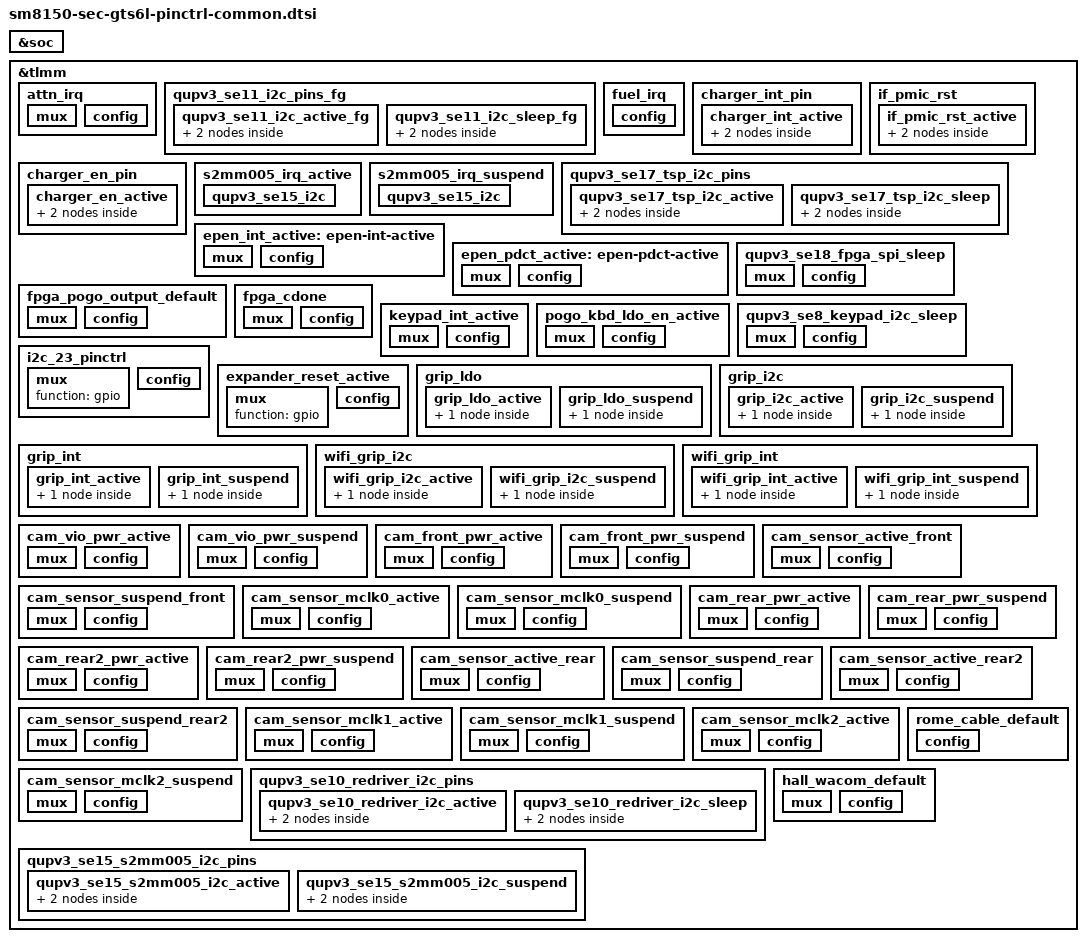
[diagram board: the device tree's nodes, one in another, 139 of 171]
/* Copyright (c) 2016-2018, The Linux Foundation. All rights reserved.
 *
 * This program is free software; you can redistribute it and/or modify
 * it under the terms of the GNU General Public License version 2 and
 * only version 2 as published by the Free Software Foundation.
 *
 * This program is distributed in the hope that it will be useful,
 * but WITHOUT ANY WARRANTY; without even the implied warranty of
 * MERCHANTABILITY or FITNESS FOR A PARTICULAR PURPOSE.  See the
 * GNU General Public License for more details.
 */

#include "sm8150-sec-gts6l-audio-pinctrl.dtsi"

&soc {
};

&tlmm {
	attn_irq: attn_irq {
		mux {
			pins = "gpio87";
			function = "gpio";
		};
		config {
			pins = "gpio87";
			input-enable;
			bias-disable;
		};
	};

	/* SE 11 pin mappings */
	qupv3_se11_i2c_pins_fg: qupv3_se11_i2c_pins_fg {
		qupv3_se11_i2c_active_fg: qupv3_se11_i2c_active_fg {
			mux {
				pins = "gpio94", "gpio95";
				function = "qup11";
			};

			config {
				pins = "gpio94", "gpio95";
				drive-strength = <2>;
				bias-disable;
				input-enable;
			};
		};

		qupv3_se11_i2c_sleep_fg: qupv3_se11_i2c_sleep_fg {
			mux {
				pins = "gpio94", "gpio95";
				function = "gpio";
			};

			config {
				pins = "gpio94", "gpio95";
				drive-strength = <2>;
				bias-disable;
				input-enable;
			};
		};
	};

	fuel_irq: fuel_irq {
		config {
			pins = "gpio37";
			bias-disable;         /* No PULL */
		};
	};

	charger_int_pin {
		//qcom,pins = <&gp 69>;
		qcom,num-grp-pins = <1>;
		qcom,pin-func = <0>;
		label = "charger_int_gpio";
		charger_int_active: charger_int_active {
			mux {
				pins = "gpio41";
				function = "gpio";				
			};
			config {
				pins = "gpio41";
				drive-strength = <2>;
				bias-disable;         /* No PULL */
			};
		};
	};
	
	if_pmic_rst {
		qcom,num-grp-pins = <1>;
		qcom,pin-func = <0>;
		label = "if_pmic_rst_gpio";
		if_pmic_rst_active: if_pmic_rst_active {
			mux {
				pins = "gpio30";
				function = "gpio";				
			};
			config {
				pins = "gpio30";
				drive-strength = <2>;
				bias-disable;         /* No PULL */
				output-high;
			};
		};
	};

 	charger_en_pin {
 		//qcom,pins = <&gp 63>;
		qcom,num-grp-pins = <1>;
		qcom,pin-func = <0>;
		label = "charger_en_gpio";
		charger_en_active: charger_en_active {
			mux {
				pins = "gpio143";
				function = "gpio";				
 			};
			config {
				pins = "gpio143";
				drive-strength = <2>;
				bias-disable;         /* No PULL */
				output-high;
			};
		};
	};
	/* add pinctrl for ccic */
	s2mm005_irq_active: s2mm005_irq_active {
		qupv3_se15_i2c {
			pins = "gpio123";
			drive-strength = <2>;
			bias-disable;
		};
	};
	s2mm005_irq_suspend: s2mm005_irq_suspend {
		qupv3_se15_i2c {
			pins = "gpio123";
			drive-strength = <2>;
			bias-disable;
		};
	};

#if 0
	muic_i2c {
		muic_i2c_active: muic_i2c_active {
			muic_i2c {
				pins = "gpio25", "gpio26";
				drive-strength = <2>;
				bias-disable;
			};
		};
		muic_i2c_suspend: muic_i2c_suspend {
			muic_i2c {
				pins = "gpio25", "gpio26";
				drive-strength = <2>;
				bias-disable;
			};
		};
	};
#endif
	/* SE 17 pin mappings */
	
	qupv3_se17_tsp_i2c_pins: qupv3_se17_tsp_i2c_pins {
		qupv3_se17_tsp_i2c_active: qupv3_se17_tsp_i2c_active {
			mux {
				pins = "gpio55", "gpio56";
				function = "qup17";
			};

			config {
				pins = "gpio55", "gpio56";
				drive-strength = <2>;
				bias-disable;
			};
		};

		qupv3_se17_tsp_i2c_sleep: qupv3_se17_tsp_i2c_sleep {
			mux {
				pins = "gpio55", "gpio56";
				function = "gpio";
			};

			config {
				pins = "gpio55", "gpio56";
				drive-strength = <2>;
				bias-disable;
			};
		};
	};

	epen_int_active: epen-int-active {
		mux {
			pins = "gpio5";
			function = "gpio";
		};
		config {
			pins = "gpio5";
			input-enable;
			bias-disable; /* No PULL */
		};
	};

	epen_pdct_active: epen-pdct-active {
		mux {
			pins = "gpio53";
			function = "gpio";
		};
		config {
			pins = "gpio53";
			input-enable;
			bias-disable;
		};
	};

	qupv3_se18_fpga_spi_sleep: qupv3_se18_fpga_spi_sleep {
		mux {
			pins = "gpio23", "gpio24", "gpio25",
						"gpio26";
			function = "gpio";
		};
		config {
			pins = "gpio23", "gpio24", "gpio25",
						"gpio26";
			drive-strength = <6>;
			bias-disable;
			input-enable;
		};
	};

	fpga_pogo_output_default: fpga_pogo_output_default {
		mux {
			pins = "gpio98", "gpio57", "gpio58";
			function = "gpio";
		};
		config {
			pins = "gpio98", "gpio57", "gpio58";
			drive-strength = <2>;
			bias-disable;
		};
	};

	fpga_cdone: fpga_cdone {
		mux {
			pins = "gpio108";
			function = "gpio";
		};
		config {
			pins = "gpio108";
			drive-strength = <2>;
			input-enable;
			bias-disable;
		};
	};

	/* pogo keyboard int pinctrl */
	keypad_int_active: keypad_int_active {
		mux {
			pins = "gpio124";
			function = "gpio";
		};

		config {
			pins = "gpio124";
			drive-strength = <2>;
			input-enable;
			bias-disable;
		};
	};

	pogo_kbd_ldo_en_active: pogo_kbd_ldo_en_active {
		mux {
			pins = "gpio65";
			function = "gpio";
		};

		config {
			pins = "gpio65";
			drive-strength = <2>;
			bias-disable;
		};
	};

	qupv3_se8_keypad_i2c_sleep: qupv3_se8_keypad_i2c_sleep {
		mux {
			pins = "gpio88", "gpio89";
			function = "gpio";
		};

		config {
			pins = "gpio88", "gpio89";
			drive-strength = <2>;
			input-enable;
			bias-disable;
		};
	};

	i2c_23_pinctrl: i2c_23_pinctrl {
		mux {
			/*pins = "gpio21",		EXPANDER_I2C_SDA_1P8
			       "gpio22";			EXPANDER_I2C_SCL_1P8 */
			function = "gpio";
		};
		config {
			/*pins = "gpio21",		EXPANDER_I2C_SDA_1P8
			       "gpio22";			EXPANDER_I2C_SCL_1P8 */
			drive-strength = <2>;
			bias-disable;
		};
	};

	expander_reset_active: expander_reset_active {
		mux {
			/*pins = "gpio29";*/
			function = "gpio";
		};
		config {
			/*pins = "gpio29";*/
			drive-strength = <2>;   /* 16 mA */
			bias-disable;
			output-high;
		};
	};

	grip_ldo {
		grip_ldo_active: grip_ldo_active {
			grip_ldo_active {
				pins = "gpio35";
				bias-disable;         /* No PULL */
				output-high;
			};
		};
		grip_ldo_suspend: grip_ldo_suspend {
			grip_ldo_suspend {
				pins = "gpio35";
				bias-disable;         /* No PULL */
				output-high;
			};
		};
	};

	grip_i2c {
		grip_i2c_active: grip_i2c_active {
			grip_i2c_active {
				pins = "gpio79", "gpio80";
				bias-disable;
			};
		};
		grip_i2c_suspend: grip_i2c_suspend {
			grip_i2c_suspend {
				pins = "gpio79", "gpio80";
				bias-disable;
			};
		};
	};

	grip_int {
		grip_int_active: grip_int_active {
			grip_int_active {
				pins = "gpio91";
				bias-disable;
			};
		};
		grip_int_suspend: grip_int_suspend {
			grip_int_suspend {
				pins = "gpio91";
				bias-disable;
			};
		};
	};

	wifi_grip_i2c {
		wifi_grip_i2c_active: wifi_grip_i2c_active {
			wifi_grip_i2c_active {
				pins = "gpio102", "gpio104";
				bias-disable;
			};
		};
		wifi_grip_i2c_suspend: wifi_grip_i2c_suspend {
			wifi_grip_i2c_suspend {
				pins = "gpio102", "gpio104";
				bias-disable;
			};
		};
	};
	
	wifi_grip_int {
		wifi_grip_int_active: wifi_grip_int_active {
			wifi_grip_int_active {
				pins = "gpio90";
				bias-disable;
			};
		};
		wifi_grip_int_suspend: wifi_grip_int_suspend {
			wifi_grip_int_suspend {
				pins = "gpio90";
				bias-disable;
			};
		};
	};

	cam_vio_pwr_active: cam_vio_pwr_active {
		/* VIO */
		mux {
			pins = "gpio54";
			function = "gpio";
		};
		config {
			pins = "gpio54";
			bias-disable; /* No PULL */
			drive-strength = <2>; /* 2 MA */
		};
	};
	
	cam_vio_pwr_suspend:cam_vio_pwr_suspend {
		/* VIO */
		mux {
			pins = "gpio54";
			function = "gpio";
		};
		config {
			pins = "gpio54";
			bias-pull-down; /* PULL DOWN */
			drive-strength = <2>; /* 2 MA */
		};
	};

	cam_front_pwr_active: cam_front_pwr_active {
		/* FRONT VANA */
		mux {
			pins = "gpio29";
			function = "gpio";
		};
		config {
			pins = "gpio29";
			bias-disable; /* No PULL */
			drive-strength = <2>; /* 2 MA */
		};
	};
	
	cam_front_pwr_suspend:cam_front_pwr_suspend {
		/* FRONT VANA */
		mux {
			pins = "gpio29";
			function = "gpio";
		};
		config {
			pins = "gpio29";
			bias-pull-down; /* PULL DOWN */
			drive-strength = <2>; /* 2 MA */
		};
	};

	cam_sensor_active_front: cam_sensor_active_front {
		/* RESET FRONT */
		mux {
			pins = "gpio82";
			function = "gpio";
		};

		config {
			pins = "gpio82";
			bias-disable; /* No PULL */
			drive-strength = <2>; /* 2 MA */
		};
	};

	cam_sensor_suspend_front: cam_sensor_suspend_front {
		/* RESET FRONT */
		mux {
			pins = "gpio82";
			function = "gpio";
		};

		config {
			pins = "gpio82";
			bias-pull-down; /* PULL DOWN */
			drive-strength = <2>; /* 2 MA */
			output-low;
		};
	};

	cam_sensor_mclk0_active: cam_sensor_mclk0_active {
		/* MCLK0 */
		mux {
			pins = "gpio13";
			function = "cam_mclk";
		};
		config {
			pins = "gpio13";
			bias-disable; /* No PULL */
			drive-strength = <4>; /* 4 MA */
		};
	};

	cam_sensor_mclk0_suspend: cam_sensor_mclk0_suspend {
		/* MCLK0 */
		mux {
			pins = "gpio13";
			function = "cam_mclk";
		};
		config {
			pins = "gpio13";
			bias-pull-down; /* PULL DOWN */
			drive-strength = <4>; /* 4 MA */
		};
	};

	cam_rear_pwr_active: cam_rear_pwr_active {
		/* REAR VANA */
		mux {
			pins = "gpio22";
			function = "gpio";
		};
		config {
			pins = "gpio22";
			bias-disable; /* No PULL */
			drive-strength = <2>; /* 2 MA */
		};
	};
	
	cam_rear_pwr_suspend:cam_rear_pwr_suspend {
		/* REAR VANA */
		mux {
			pins = "gpio22";
			function = "gpio";
		};
		config {
			pins = "gpio22";
			bias-pull-down; /* PULL DOWN */
			drive-strength = <2>; /* 2 MA */
		};
	};
	
	cam_rear2_pwr_active: cam_rear2_pwr_active {
		/* REAR VANA */
		mux {
			pins = "gpio16";
			function = "gpio";
		};
		config {
			pins = "gpio16";
			bias-disable; /* No PULL */
			drive-strength = <2>; /* 2 MA */
		};
	};
	
	cam_rear2_pwr_suspend:cam_rear2_pwr_suspend {
		/* REAR VANA */
		mux {
			pins = "gpio16";
			function = "gpio";
		};
		config {
			pins = "gpio16";
			bias-pull-down; /* PULL DOWN */
			drive-strength = <2>; /* 2 MA */
		};
	};	

	cam_sensor_active_rear: cam_sensor_active_rear {
		/* RESET REAR */
		mux {
			pins = "gpio92";
			function = "gpio";
		};
		config {
			pins = "gpio92";
			bias-disable; /* No PULL */
			drive-strength = <2>; /* 2 MA */
		};
	};

	cam_sensor_suspend_rear: cam_sensor_suspend_rear {
		/* RESET REAR */
		mux {
			pins = "gpio92";
			function = "gpio";
		};
		config {
			pins = "gpio92";
			bias-pull-down; /* PULL DOWN */
			drive-strength = <2>; /* 2 MA */
			output-low;
		};
	};
	
	cam_sensor_active_rear2: cam_sensor_active_rear2 {
		/* RESET REAR */
		mux {
			pins = "gpio21";
			function = "gpio";
		};
		config {
			pins = "gpio21";
			bias-disable; /* No PULL */
			drive-strength = <2>; /* 2 MA */
		};
	};

	cam_sensor_suspend_rear2: cam_sensor_suspend_rear2 {
		/* RESET REAR */
		mux {
			pins = "gpio21";
			function = "gpio";
		};
		config {
			pins = "gpio21";
			bias-pull-down; /* PULL DOWN */
			drive-strength = <2>; /* 2 MA */
			output-low;
		};
	};	

	cam_sensor_mclk1_active: cam_sensor_mclk1_active {
		/* MCLK1 */
		mux {
			pins = "gpio14";
			function = "cam_mclk";
		};
		config {
			pins = "gpio14";
			bias-disable; /* No PULL */
			drive-strength = <4>; /* 4 MA */
		};
	};

	cam_sensor_mclk1_suspend: cam_sensor_mclk1_suspend {
		/* MCLK1 */
		mux {
			pins = "gpio14";
			function = "cam_mclk";
		};
		config {
			pins = "gpio14";
			bias-pull-down; /* PULL DOWN */
			drive-strength = <4>; /* 4 MA */
		};
	};

	cam_sensor_mclk2_active: cam_sensor_mclk2_active {
		/* MCLK2 */
		mux {
			pins = "gpio15";
			function = "cam_mclk";
		};

		config {
			pins = "gpio15";
			bias-disable; /* No PULL */
			drive-strength = <4>; /* 4 MA */
		};
	};

	cam_sensor_mclk2_suspend: cam_sensor_mclk2_suspend {
		/* MCLK2 */
		mux {
			pins = "gpio15";
			function = "cam_mclk";
		};

		config {
			pins = "gpio15";
			bias-pull-down; /* PULL DOWN */
			drive-strength = <4>; /* 4 MA */
		};
	};

	/* SE 10 pin mappings */
	qupv3_se10_redriver_i2c_pins: qupv3_se10_redriver_i2c_pins {
		qupv3_se10_redriver_i2c_active: qupv3_se10_redriver_i2c_active {
			mux {
				pins = "gpio9", "gpio10";
				function = "qup10";
			};

			config {
				pins = "gpio9", "gpio10";
				drive-strength = <2>;
				bias-disable; /* No PULL */
			};
		};

		qupv3_se10_redriver_i2c_sleep: qupv3_se10_redriver_i2c_sleep {
			mux {
				pins = "gpio9", "gpio10";
				function = "gpio";
			};

			config {
				pins = "gpio9", "gpio10";
				drive-strength = <2>;
				bias-disable; /* No PULL */
			};
		};
	};

	/* SE 15 pin mappings */
	qupv3_se15_s2mm005_i2c_pins: qupv3_se15_s2mm005_i2c_pins {
		qupv3_se15_s2mm005_i2c_active: qupv3_se15_s2mm005_i2c_active {
			mux {
				pins = "gpio27", "gpio28";
				function = "qup15";
			};

			config {
				pins = "gpio27", "gpio28";
				drive-strength = <2>;
				bias-disable;
				input-enable;
			};
		};

		qupv3_se15_s2mm005_i2c_suspend: qupv3_se15_s2mm005_i2c_suspend {
			mux {
				pins = "gpio27", "gpio28";
				function = "gpio";
			};

			config {
				pins = "gpio27", "gpio28";
				drive-strength = <2>;
				bias-disable;
				input-enable;
			};
		};
	};

	rome_cable_default: rome_cable_default {
		config {
			pins = "gpio116","gpio119";
			bias-disable;
		};
	};

	hall_wacom_default: hall_wacom_default {
		mux {
			pins = "gpio81";
			function = "gpio";
		};
		config {
			pins = "gpio81";
			drive-strength = <2>;
			bias-disable;
		};
	};
};
